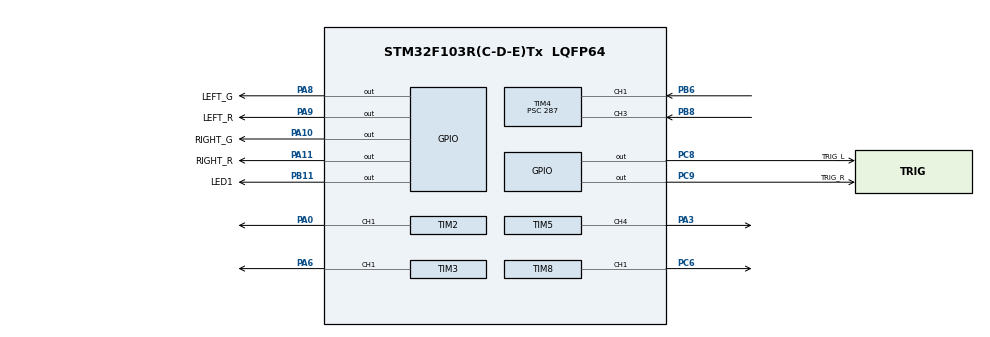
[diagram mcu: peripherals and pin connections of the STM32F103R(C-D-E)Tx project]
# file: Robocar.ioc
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Mcu.Family=STM32F1
Mcu.Name=STM32F103R(C-D-E)Tx
Mcu.Package=LQFP64
NVIC.PriorityGroup=NVIC_PRIORITYGROUP_4
PA0-WKUP.Signal=S_TIM2_CH1_ETR
PA10.GPIO_Label=RIGHT_G
PA10.Signal=GPIO_Output
PA11.GPIO_Label=RIGHT_R
PA11.Signal=GPIO_Output
PA13.Mode=JTAG_5_pins
PA13.Signal=SYS_JTMS-SWDIO
PA14.Mode=JTAG_5_pins
PA14.Signal=SYS_JTCK-SWCLK
PA15.Mode=JTAG_5_pins
PA15.Signal=SYS_JTDI
PA3.Signal=S_TIM5_CH4
PA6.Signal=S_TIM3_CH1
PA8.GPIO_Label=LEFT_G
PA8.Signal=GPIO_Output
PA9.GPIO_Label=LEFT_R
PA9.Signal=GPIO_Output
PB11.GPIO_Label=LED1
PB11.GPIO_ModeDefaultOutputPP=GPIO_MODE_OUTPUT_PP
PB11.PinState=GPIO_PIN_SET
PB11.Signal=GPIO_Output
PB3.Mode=JTAG_5_pins
PB3.Signal=SYS_JTDO-TRACESWO
PB4.Mode=JTAG_5_pins
PB4.Signal=SYS_NJTRST
PB6.Signal=S_TIM4_CH1
PB8.Signal=S_TIM4_CH3
PC6.Signal=S_TIM8_CH1
PC8.GPIO_Label=TRIG_L
PC8.Signal=GPIO_Output
PC9.GPIO_Label=TRIG_R
PC9.Signal=GPIO_Output
PD0-OSC_IN.Mode=HSE-External-Oscillator
PD0-OSC_IN.Signal=RCC_OSC_IN
PD1-OSC_OUT.Mode=HSE-External-Oscillator
PD1-OSC_OUT.Signal=RCC_OSC_OUT
ProjectManager.HeapSize=0x200
ProjectManager.StackSize=0x400
ProjectManager.TargetToolchain=EWARM V7
RCC.AHBFreq_Value=72000000
RCC.APB1CLKDivider=RCC_HCLK_DIV2
RCC.APB1Freq_Value=36000000
RCC.APB1TimFreq_Value=72000000
RCC.APB2Freq_Value=72000000
RCC.APB2TimFreq_Value=72000000
RCC.HCLKFreq_Value=72000000
RCC.PLLMUL=RCC_PLL_MUL9
RCC.PLLSourceVirtual=RCC_PLLSOURCE_HSE
RCC.SYSCLKFreq_VALUE=72000000
RCC.SYSCLKSource=RCC_SYSCLKSOURCE_PLLCLK
RCC.USBFreq_Value=72000000
SH.S_TIM2_CH1_ETR.0=TIM2_CH1,PWM Generation1 CH1
SH.S_TIM3_CH1.0=TIM3_CH1,PWM Generation1 CH1
SH.S_TIM4_CH1.0=TIM4_CH1,Input_Capture1_from_TI1
SH.S_TIM4_CH1.1=TIM4_CH1,Input_Capture2_from_TI1
SH.S_TIM4_CH3.0=TIM4_CH3,Input_Capture3_from_TI3
SH.S_TIM4_CH3.1=TIM4_CH3,Input_Capture4_from_TI3
SH.S_TIM5_CH4.0=TIM5_CH4,PWM Generation4 CH4
SH.S_TIM8_CH1.0=TIM8_CH1,PWM Generation1 CH1
TIM2.AutoReloadPreload=TIM_AUTORELOAD_PRELOAD_ENABLE
TIM2.Channel-PWM\ Generation1\ CH1=TIM_CHANNEL_1
TIM2.ClockDivision=TIM_CLOCKDIVISION_DIV1
TIM2.Period=1999
TIM2.Prescaler=71
TIM2.Pulse-PWM\ Generation1\ CH1=500
TIM3.AutoReloadPreload=TIM_AUTORELOAD_PRELOAD_ENABLE
TIM3.Channel-PWM\ Generation1\ CH1=TIM_CHANNEL_1
TIM3.OCFastMode_PWM-PWM\ Generation1\ CH1=TIM_OCFAST_DISABLE
TIM3.Period=10000
TIM3.Prescaler=144
TIM4.Channel-Input_Capture1_from_TI1=TIM_CHANNEL_1
TIM4.Channel-Input_Capture2_from_TI1=TIM_CHANNEL_2
TIM4.Channel-Input_Capture3_from_TI3=TIM_CHANNEL_3
TIM4.Channel-Input_Capture4_from_TI3=TIM_CHANNEL_4
TIM4.ICPolarity_CH2=TIM_INPUTCHANNELPOLARITY_FALLING
TIM4.ICPolarity_CH4=TIM_INPUTCHANNELPOLARITY_FALLING
TIM4.Period=0xffff
TIM4.Prescaler=287
TIM5.Channel-PWM\ Generation4\ CH4=TIM_CHANNEL_4
TIM8.Channel-PWM\ Generation1\ CH1=TIM_CHANNEL_1
VP_TIM2_VS_ClockSourceINT.Mode=Internal
VP_TIM3_VS_ClockSourceINT.Mode=Internal
VP_TIM4_VS_ClockSourceINT.Mode=Internal
VP_TIM5_VS_ClockSourceINT.Mode=Internal
VP_TIM8_VS_ClockSourceINT.Mode=Internal
board=custom

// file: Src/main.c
/* USER CODE BEGIN Header */
/**
  ******************************************************************************
  * @file           : main.c
  * @brief          : Main program body
  ******************************************************************************
  ** This notice applies to any and all portions of this file
  * that are not between comment pairs USER CODE BEGIN and
  * USER CODE END. Other portions of this file, whether
  * inserted by the user or by software development tools
  * are owned by their respective copyright owners.
  *
  * COPYRIGHT(c) 2019 STMicroelectronics
  *
  * Redistribution and use in source and binary forms, with or without modification,
  * are permitted provided that the following conditions are met:
  *   1. Redistributions of source code must retain the above copyright notice,
  *      this list of conditions and the following disclaimer.
  *   2. Redistributions in binary form must reproduce the above copyright notice,
  *      this list of conditions and the following disclaimer in the documentation
  *      and/or other materials provided with the distribution.
  *   3. Neither the name of STMicroelectronics nor the names of its contributors
  *      may be used to endorse or promote products derived from this software
  *      without specific prior written permission.
  *
  * THIS SOFTWARE IS PROVIDED BY THE COPYRIGHT HOLDERS AND CONTRIBUTORS "AS IS"
  * AND ANY EXPRESS OR IMPLIED WARRANTIES, INCLUDING, BUT NOT LIMITED TO, THE
  * IMPLIED WARRANTIES OF MERCHANTABILITY AND FITNESS FOR A PARTICULAR PURPOSE ARE
  * DISCLAIMED. IN NO EVENT SHALL THE COPYRIGHT HOLDER OR CONTRIBUTORS BE LIABLE
  * FOR ANY DIRECT, INDIRECT, INCIDENTAL, SPECIAL, EXEMPLARY, OR CONSEQUENTIAL
  * DAMAGES (INCLUDING, BUT NOT LIMITED TO, PROCUREMENT OF SUBSTITUTE GOODS OR
  * SERVICES; LOSS OF USE, DATA, OR PROFITS; OR BUSINESS INTERRUPTION) HOWEVER
  * CAUSED AND ON ANY THEORY OF LIABILITY, WHETHER IN CONTRACT, STRICT LIABILITY,
  * OR TORT (INCLUDING NEGLIGENCE OR OTHERWISE) ARISING IN ANY WAY OUT OF THE USE
  * OF THIS SOFTWARE, EVEN IF ADVISED OF THE POSSIBILITY OF SUCH DAMAGE.
  *
  ******************************************************************************
  */
/* USER CODE END Header */

#include "main.h"

/* USER CODE BEGIN Includes */
#include "robocar.hpp"
/* USER CODE END Includes */

void SystemClock_Config(void);
static void MX_GPIO_Init(void);
static void MX_TIM2_Init(void);
static void MX_TIM4_Init(void);
static void MX_TIM5_Init(void);
static void MX_TIM8_Init(void);
static void MX_TIM3_Init(void);

int main(void)
{

  /* MCU Configuration--------------------------------------------------------*/

  /* Reset of all peripherals, Initializes the Flash interface and the Systick. */

  LL_APB2_GRP1_EnableClock(LL_APB2_GRP1_PERIPH_AFIO);
  LL_APB1_GRP1_EnableClock(LL_APB1_GRP1_PERIPH_PWR);

  NVIC_SetPriorityGrouping(NVIC_PRIORITYGROUP_4);

  /* System interrupt init*/

  /** ENABLE: Full SWJ (JTAG-DP + SW-DP): Reset State
  */
  LL_GPIO_AF_EnableRemap_SWJ();

  /* Configure the system clock */
  SystemClock_Config();

  /* Initialize all configured peripherals */
  MX_GPIO_Init();
  MX_TIM2_Init();
  MX_TIM4_Init();
  MX_TIM5_Init();
  MX_TIM8_Init();
  MX_TIM3_Init();
  /* USER CODE BEGIN 2 */
  Robocar robocar = Robocar();
  /* USER CODE END 2 */

  /* Infinite loop */
  /* USER CODE BEGIN WHILE */

  while (1)
  {
    robocar.Run();
    /* USER CODE END WHILE */

  }
}

void SystemClock_Config(void)
{
  LL_FLASH_SetLatency(LL_FLASH_LATENCY_2);

   if(LL_FLASH_GetLatency() != LL_FLASH_LATENCY_2)
  {
    Error_Handler();
  }
  LL_RCC_HSE_Enable();

   /* Wait till HSE is ready */
  while(LL_RCC_HSE_IsReady() != 1)
  {

  }
  LL_RCC_PLL_ConfigDomain_SYS(LL_RCC_PLLSOURCE_HSE_DIV_1, LL_RCC_PLL_MUL_9);
  LL_RCC_PLL_Enable();

   /* Wait till PLL is ready */
  while(LL_RCC_PLL_IsReady() != 1)
  {

  }
  LL_RCC_SetAHBPrescaler(LL_RCC_SYSCLK_DIV_1);
  LL_RCC_SetAPB1Prescaler(LL_RCC_APB1_DIV_2);
  LL_RCC_SetAPB2Prescaler(LL_RCC_APB2_DIV_1);
  LL_RCC_SetSysClkSource(LL_RCC_SYS_CLKSOURCE_PLL);

   /* Wait till System clock is ready */
  while(LL_RCC_GetSysClkSource() != LL_RCC_SYS_CLKSOURCE_STATUS_PLL)
  {

  }
  LL_Init1msTick(72000000);
  LL_SYSTICK_SetClkSource(LL_SYSTICK_CLKSOURCE_HCLK);
  LL_SetSystemCoreClock(72000000);
}

static void MX_TIM2_Init(void)
{

  LL_TIM_InitTypeDef TIM_InitStruct = {0};
  LL_TIM_OC_InitTypeDef TIM_OC_InitStruct = {0};

  LL_GPIO_InitTypeDef GPIO_InitStruct = {0};

  /* Peripheral clock enable */
  LL_APB1_GRP1_EnableClock(LL_APB1_GRP1_PERIPH_TIM2);

  TIM_InitStruct.Prescaler = 71;
  TIM_InitStruct.CounterMode = LL_TIM_COUNTERMODE_UP;
  TIM_InitStruct.Autoreload = 1999;
  TIM_InitStruct.ClockDivision = LL_TIM_CLOCKDIVISION_DIV1;
  LL_TIM_Init(TIM2, &TIM_InitStruct);
  LL_TIM_EnableARRPreload(TIM2);
  LL_TIM_SetClockSource(TIM2, LL_TIM_CLOCKSOURCE_INTERNAL);
  LL_TIM_OC_EnablePreload(TIM2, LL_TIM_CHANNEL_CH1);
  TIM_OC_InitStruct.OCMode = LL_TIM_OCMODE_PWM1;
  TIM_OC_InitStruct.OCState = LL_TIM_OCSTATE_DISABLE;
  TIM_OC_InitStruct.OCNState = LL_TIM_OCSTATE_DISABLE;
  TIM_OC_InitStruct.CompareValue = 500;
  TIM_OC_InitStruct.OCPolarity = LL_TIM_OCPOLARITY_HIGH;
  LL_TIM_OC_Init(TIM2, LL_TIM_CHANNEL_CH1, &TIM_OC_InitStruct);
  LL_TIM_OC_DisableFast(TIM2, LL_TIM_CHANNEL_CH1);
  LL_TIM_SetTriggerOutput(TIM2, LL_TIM_TRGO_RESET);
  LL_TIM_DisableMasterSlaveMode(TIM2);
  LL_APB2_GRP1_EnableClock(LL_APB2_GRP1_PERIPH_GPIOA);
  /**TIM2 GPIO Configuration
  PA0-WKUP   ------> TIM2_CH1
  */
  GPIO_InitStruct.Pin = LL_GPIO_PIN_0;
  GPIO_InitStruct.Mode = LL_GPIO_MODE_ALTERNATE;
  GPIO_InitStruct.Speed = LL_GPIO_SPEED_FREQ_LOW;
  GPIO_InitStruct.OutputType = LL_GPIO_OUTPUT_PUSHPULL;
  LL_GPIO_Init(GPIOA, &GPIO_InitStruct);

}

static void MX_TIM3_Init(void)
{

  LL_TIM_InitTypeDef TIM_InitStruct = {0};
  LL_TIM_OC_InitTypeDef TIM_OC_InitStruct = {0};

  LL_GPIO_InitTypeDef GPIO_InitStruct = {0};

  /* Peripheral clock enable */
  LL_APB1_GRP1_EnableClock(LL_APB1_GRP1_PERIPH_TIM3);

  TIM_InitStruct.Prescaler = 144;
  TIM_InitStruct.CounterMode = LL_TIM_COUNTERMODE_UP;
  TIM_InitStruct.Autoreload = 10000;
  TIM_InitStruct.ClockDivision = LL_TIM_CLOCKDIVISION_DIV1;
  LL_TIM_Init(TIM3, &TIM_InitStruct);
  LL_TIM_EnableARRPreload(TIM3);
  LL_TIM_SetClockSource(TIM3, LL_TIM_CLOCKSOURCE_INTERNAL);
  LL_TIM_OC_EnablePreload(TIM3, LL_TIM_CHANNEL_CH1);
  TIM_OC_InitStruct.OCMode = LL_TIM_OCMODE_PWM1;
  TIM_OC_InitStruct.OCState = LL_TIM_OCSTATE_DISABLE;
  TIM_OC_InitStruct.OCNState = LL_TIM_OCSTATE_DISABLE;
  TIM_OC_InitStruct.CompareValue = 0;
  TIM_OC_InitStruct.OCPolarity = LL_TIM_OCPOLARITY_HIGH;
  LL_TIM_OC_Init(TIM3, LL_TIM_CHANNEL_CH1, &TIM_OC_InitStruct);
  LL_TIM_OC_DisableFast(TIM3, LL_TIM_CHANNEL_CH1);
  LL_TIM_SetTriggerOutput(TIM3, LL_TIM_TRGO_RESET);
  LL_TIM_DisableMasterSlaveMode(TIM3);
  LL_APB2_GRP1_EnableClock(LL_APB2_GRP1_PERIPH_GPIOA);
  /**TIM3 GPIO Configuration
  PA6   ------> TIM3_CH1
  */
  GPIO_InitStruct.Pin = LL_GPIO_PIN_6;
  GPIO_InitStruct.Mode = LL_GPIO_MODE_ALTERNATE;
  GPIO_InitStruct.Speed = LL_GPIO_SPEED_FREQ_LOW;
  GPIO_InitStruct.OutputType = LL_GPIO_OUTPUT_PUSHPULL;
  LL_GPIO_Init(GPIOA, &GPIO_InitStruct);

}

static void MX_TIM4_Init(void)
{

  LL_TIM_InitTypeDef TIM_InitStruct = {0};

  LL_GPIO_InitTypeDef GPIO_InitStruct = {0};

  /* Peripheral clock enable */
  LL_APB1_GRP1_EnableClock(LL_APB1_GRP1_PERIPH_TIM4);

  LL_APB2_GRP1_EnableClock(LL_APB2_GRP1_PERIPH_GPIOB);
  /**TIM4 GPIO Configuration
  PB6   ------> TIM4_CH1
  PB8   ------> TIM4_CH3
  */
  GPIO_InitStruct.Pin = LL_GPIO_PIN_6|LL_GPIO_PIN_8;
  GPIO_InitStruct.Mode = LL_GPIO_MODE_FLOATING;
  LL_GPIO_Init(GPIOB, &GPIO_InitStruct);

  TIM_InitStruct.Prescaler = 287;
  TIM_InitStruct.CounterMode = LL_TIM_COUNTERMODE_UP;
  TIM_InitStruct.Autoreload = 0xffff;
  TIM_InitStruct.ClockDivision = LL_TIM_CLOCKDIVISION_DIV1;
  LL_TIM_Init(TIM4, &TIM_InitStruct);
  LL_TIM_DisableARRPreload(TIM4);
  LL_TIM_SetClockSource(TIM4, LL_TIM_CLOCKSOURCE_INTERNAL);
  LL_TIM_SetTriggerOutput(TIM4, LL_TIM_TRGO_RESET);
  LL_TIM_DisableMasterSlaveMode(TIM4);
  LL_TIM_IC_SetActiveInput(TIM4, LL_TIM_CHANNEL_CH1, LL_TIM_ACTIVEINPUT_DIRECTTI);
  LL_TIM_IC_SetPrescaler(TIM4, LL_TIM_CHANNEL_CH1, LL_TIM_ICPSC_DIV1);
  LL_TIM_IC_SetFilter(TIM4, LL_TIM_CHANNEL_CH1, LL_TIM_IC_FILTER_FDIV1);
  LL_TIM_IC_SetPolarity(TIM4, LL_TIM_CHANNEL_CH1, LL_TIM_IC_POLARITY_RISING);
  LL_TIM_IC_SetActiveInput(TIM4, LL_TIM_CHANNEL_CH2, LL_TIM_ACTIVEINPUT_INDIRECTTI);
  LL_TIM_IC_SetPrescaler(TIM4, LL_TIM_CHANNEL_CH2, LL_TIM_ICPSC_DIV1);
  LL_TIM_IC_SetFilter(TIM4, LL_TIM_CHANNEL_CH2, LL_TIM_IC_FILTER_FDIV1);
  LL_TIM_IC_SetPolarity(TIM4, LL_TIM_CHANNEL_CH2, LL_TIM_IC_POLARITY_FALLING);
  LL_TIM_IC_SetActiveInput(TIM4, LL_TIM_CHANNEL_CH3, LL_TIM_ACTIVEINPUT_DIRECTTI);
  LL_TIM_IC_SetPrescaler(TIM4, LL_TIM_CHANNEL_CH3, LL_TIM_ICPSC_DIV1);
  LL_TIM_IC_SetFilter(TIM4, LL_TIM_CHANNEL_CH3, LL_TIM_IC_FILTER_FDIV1);
  LL_TIM_IC_SetPolarity(TIM4, LL_TIM_CHANNEL_CH3, LL_TIM_IC_POLARITY_RISING);
  LL_TIM_IC_SetActiveInput(TIM4, LL_TIM_CHANNEL_CH4, LL_TIM_ACTIVEINPUT_INDIRECTTI);
  LL_TIM_IC_SetPrescaler(TIM4, LL_TIM_CHANNEL_CH4, LL_TIM_ICPSC_DIV1);
  LL_TIM_IC_SetFilter(TIM4, LL_TIM_CHANNEL_CH4, LL_TIM_IC_FILTER_FDIV1);
  LL_TIM_IC_SetPolarity(TIM4, LL_TIM_CHANNEL_CH4, LL_TIM_IC_POLARITY_FALLING);

}

static void MX_TIM5_Init(void)
{

  LL_TIM_InitTypeDef TIM_InitStruct = {0};
  LL_TIM_OC_InitTypeDef TIM_OC_InitStruct = {0};

  LL_GPIO_InitTypeDef GPIO_InitStruct = {0};

  /* Peripheral clock enable */
  LL_APB1_GRP1_EnableClock(LL_APB1_GRP1_PERIPH_TIM5);

  TIM_InitStruct.Prescaler = 0;
  TIM_InitStruct.CounterMode = LL_TIM_COUNTERMODE_UP;
  TIM_InitStruct.Autoreload = 0;
  TIM_InitStruct.ClockDivision = LL_TIM_CLOCKDIVISION_DIV1;
  LL_TIM_Init(TIM5, &TIM_InitStruct);
  LL_TIM_DisableARRPreload(TIM5);
  LL_TIM_SetClockSource(TIM5, LL_TIM_CLOCKSOURCE_INTERNAL);
  LL_TIM_OC_EnablePreload(TIM5, LL_TIM_CHANNEL_CH4);
  TIM_OC_InitStruct.OCMode = LL_TIM_OCMODE_PWM1;
  TIM_OC_InitStruct.OCState = LL_TIM_OCSTATE_DISABLE;
  TIM_OC_InitStruct.OCNState = LL_TIM_OCSTATE_DISABLE;
  TIM_OC_InitStruct.CompareValue = 0;
  TIM_OC_InitStruct.OCPolarity = LL_TIM_OCPOLARITY_HIGH;
  LL_TIM_OC_Init(TIM5, LL_TIM_CHANNEL_CH4, &TIM_OC_InitStruct);
  LL_TIM_OC_DisableFast(TIM5, LL_TIM_CHANNEL_CH4);
  LL_TIM_SetTriggerOutput(TIM5, LL_TIM_TRGO_RESET);
  LL_TIM_DisableMasterSlaveMode(TIM5);
  LL_APB2_GRP1_EnableClock(LL_APB2_GRP1_PERIPH_GPIOA);
  /**TIM5 GPIO Configuration
  PA3   ------> TIM5_CH4
  */
  GPIO_InitStruct.Pin = LL_GPIO_PIN_3;
  GPIO_InitStruct.Mode = LL_GPIO_MODE_ALTERNATE;
  GPIO_InitStruct.Speed = LL_GPIO_SPEED_FREQ_LOW;
  GPIO_InitStruct.OutputType = LL_GPIO_OUTPUT_PUSHPULL;
  LL_GPIO_Init(GPIOA, &GPIO_InitStruct);

}

static void MX_TIM8_Init(void)
{

  LL_TIM_InitTypeDef TIM_InitStruct = {0};
  LL_TIM_OC_InitTypeDef TIM_OC_InitStruct = {0};
  LL_TIM_BDTR_InitTypeDef TIM_BDTRInitStruct = {0};

  LL_GPIO_InitTypeDef GPIO_InitStruct = {0};

  /* Peripheral clock enable */
  LL_APB2_GRP1_EnableClock(LL_APB2_GRP1_PERIPH_TIM8);

  TIM_InitStruct.Prescaler = 0;
  TIM_InitStruct.CounterMode = LL_TIM_COUNTERMODE_UP;
  TIM_InitStruct.Autoreload = 0;
  TIM_InitStruct.ClockDivision = LL_TIM_CLOCKDIVISION_DIV1;
  TIM_InitStruct.RepetitionCounter = 0;
  LL_TIM_Init(TIM8, &TIM_InitStruct);
  LL_TIM_DisableARRPreload(TIM8);
  LL_TIM_SetClockSource(TIM8, LL_TIM_CLOCKSOURCE_INTERNAL);
  LL_TIM_OC_EnablePreload(TIM8, LL_TIM_CHANNEL_CH1);
  TIM_OC_InitStruct.OCMode = LL_TIM_OCMODE_PWM1;
  TIM_OC_InitStruct.OCState = LL_TIM_OCSTATE_DISABLE;
  TIM_OC_InitStruct.OCNState = LL_TIM_OCSTATE_DISABLE;
  TIM_OC_InitStruct.CompareValue = 0;
  TIM_OC_InitStruct.OCPolarity = LL_TIM_OCPOLARITY_HIGH;
  TIM_OC_InitStruct.OCNPolarity = LL_TIM_OCPOLARITY_HIGH;
  TIM_OC_InitStruct.OCIdleState = LL_TIM_OCIDLESTATE_LOW;
  TIM_OC_InitStruct.OCNIdleState = LL_TIM_OCIDLESTATE_LOW;
  LL_TIM_OC_Init(TIM8, LL_TIM_CHANNEL_CH1, &TIM_OC_InitStruct);
  LL_TIM_OC_DisableFast(TIM8, LL_TIM_CHANNEL_CH1);
  LL_TIM_SetTriggerOutput(TIM8, LL_TIM_TRGO_RESET);
  LL_TIM_DisableMasterSlaveMode(TIM8);
  TIM_BDTRInitStruct.OSSRState = LL_TIM_OSSR_DISABLE;
  TIM_BDTRInitStruct.OSSIState = LL_TIM_OSSI_DISABLE;
  TIM_BDTRInitStruct.LockLevel = LL_TIM_LOCKLEVEL_OFF;
  TIM_BDTRInitStruct.DeadTime = 0;
  TIM_BDTRInitStruct.BreakState = LL_TIM_BREAK_DISABLE;
  TIM_BDTRInitStruct.BreakPolarity = LL_TIM_BREAK_POLARITY_HIGH;
  TIM_BDTRInitStruct.AutomaticOutput = LL_TIM_AUTOMATICOUTPUT_DISABLE;
  LL_TIM_BDTR_Init(TIM8, &TIM_BDTRInitStruct);
  LL_APB2_GRP1_EnableClock(LL_APB2_GRP1_PERIPH_GPIOC);
  /**TIM8 GPIO Configuration
  PC6   ------> TIM8_CH1
  */
  GPIO_InitStruct.Pin = LL_GPIO_PIN_6;
  GPIO_InitStruct.Mode = LL_GPIO_MODE_ALTERNATE;
  GPIO_InitStruct.Speed = LL_GPIO_SPEED_FREQ_LOW;
  GPIO_InitStruct.OutputType = LL_GPIO_OUTPUT_PUSHPULL;
  LL_GPIO_Init(GPIOC, &GPIO_InitStruct);

}

static void MX_GPIO_Init(void)
{
  LL_GPIO_InitTypeDef GPIO_InitStruct = {0};

  /* GPIO Ports Clock Enable */
  LL_APB2_GRP1_EnableClock(LL_APB2_GRP1_PERIPH_GPIOC);
  LL_APB2_GRP1_EnableClock(LL_APB2_GRP1_PERIPH_GPIOD);
  LL_APB2_GRP1_EnableClock(LL_APB2_GRP1_PERIPH_GPIOA);
  LL_APB2_GRP1_EnableClock(LL_APB2_GRP1_PERIPH_GPIOB);

  /**/
  LL_GPIO_SetOutputPin(LED1_GPIO_Port, LED1_Pin);

  /**/
  LL_GPIO_ResetOutputPin(GPIOC, TRIG_L_Pin|TRIG_R_Pin);

  /**/
  LL_GPIO_ResetOutputPin(GPIOA, LEFT_G_Pin|LEFT_R_Pin|RIGHT_G_Pin|RIGHT_R_Pin);

  /**/
  GPIO_InitStruct.Pin = LL_GPIO_PIN_13|LL_GPIO_PIN_14|LL_GPIO_PIN_15|LL_GPIO_PIN_0
                          |LL_GPIO_PIN_1|LL_GPIO_PIN_2|LL_GPIO_PIN_3|LL_GPIO_PIN_4
                          |LL_GPIO_PIN_5|LL_GPIO_PIN_7|LL_GPIO_PIN_10|LL_GPIO_PIN_11
                          |LL_GPIO_PIN_12;
  GPIO_InitStruct.Mode = LL_GPIO_MODE_ANALOG;
  LL_GPIO_Init(GPIOC, &GPIO_InitStruct);

  /**/
  GPIO_InitStruct.Pin = LL_GPIO_PIN_1|LL_GPIO_PIN_2|LL_GPIO_PIN_4|LL_GPIO_PIN_5
                          |LL_GPIO_PIN_7|LL_GPIO_PIN_12;
  GPIO_InitStruct.Mode = LL_GPIO_MODE_ANALOG;
  LL_GPIO_Init(GPIOA, &GPIO_InitStruct);

  /**/
  GPIO_InitStruct.Pin = LL_GPIO_PIN_0|LL_GPIO_PIN_1|LL_GPIO_PIN_2|LL_GPIO_PIN_10
                          |LL_GPIO_PIN_12|LL_GPIO_PIN_13|LL_GPIO_PIN_14|LL_GPIO_PIN_15
                          |LL_GPIO_PIN_5|LL_GPIO_PIN_7|LL_GPIO_PIN_9;
  GPIO_InitStruct.Mode = LL_GPIO_MODE_ANALOG;
  LL_GPIO_Init(GPIOB, &GPIO_InitStruct);

  /**/
  GPIO_InitStruct.Pin = LED1_Pin;
  GPIO_InitStruct.Mode = LL_GPIO_MODE_OUTPUT;
  GPIO_InitStruct.Speed = LL_GPIO_SPEED_FREQ_LOW;
  GPIO_InitStruct.OutputType = LL_GPIO_OUTPUT_PUSHPULL;
  LL_GPIO_Init(LED1_GPIO_Port, &GPIO_InitStruct);

  /**/
  GPIO_InitStruct.Pin = TRIG_L_Pin|TRIG_R_Pin;
  GPIO_InitStruct.Mode = LL_GPIO_MODE_OUTPUT;
  GPIO_InitStruct.Speed = LL_GPIO_SPEED_FREQ_LOW;
  GPIO_InitStruct.OutputType = LL_GPIO_OUTPUT_PUSHPULL;
  LL_GPIO_Init(GPIOC, &GPIO_InitStruct);

  /**/
  GPIO_InitStruct.Pin = LEFT_G_Pin|LEFT_R_Pin|RIGHT_G_Pin|RIGHT_R_Pin;
  GPIO_InitStruct.Mode = LL_GPIO_MODE_OUTPUT;
  GPIO_InitStruct.Speed = LL_GPIO_SPEED_FREQ_LOW;
  GPIO_InitStruct.OutputType = LL_GPIO_OUTPUT_PUSHPULL;
  LL_GPIO_Init(GPIOA, &GPIO_InitStruct);

  /**/
  GPIO_InitStruct.Pin = LL_GPIO_PIN_2;
  GPIO_InitStruct.Mode = LL_GPIO_MODE_ANALOG;
  LL_GPIO_Init(GPIOD, &GPIO_InitStruct);

}

void Error_Handler(void)
{
}

/************************ (C) COPYRIGHT STMicroelectronics *****END OF FILE****/
